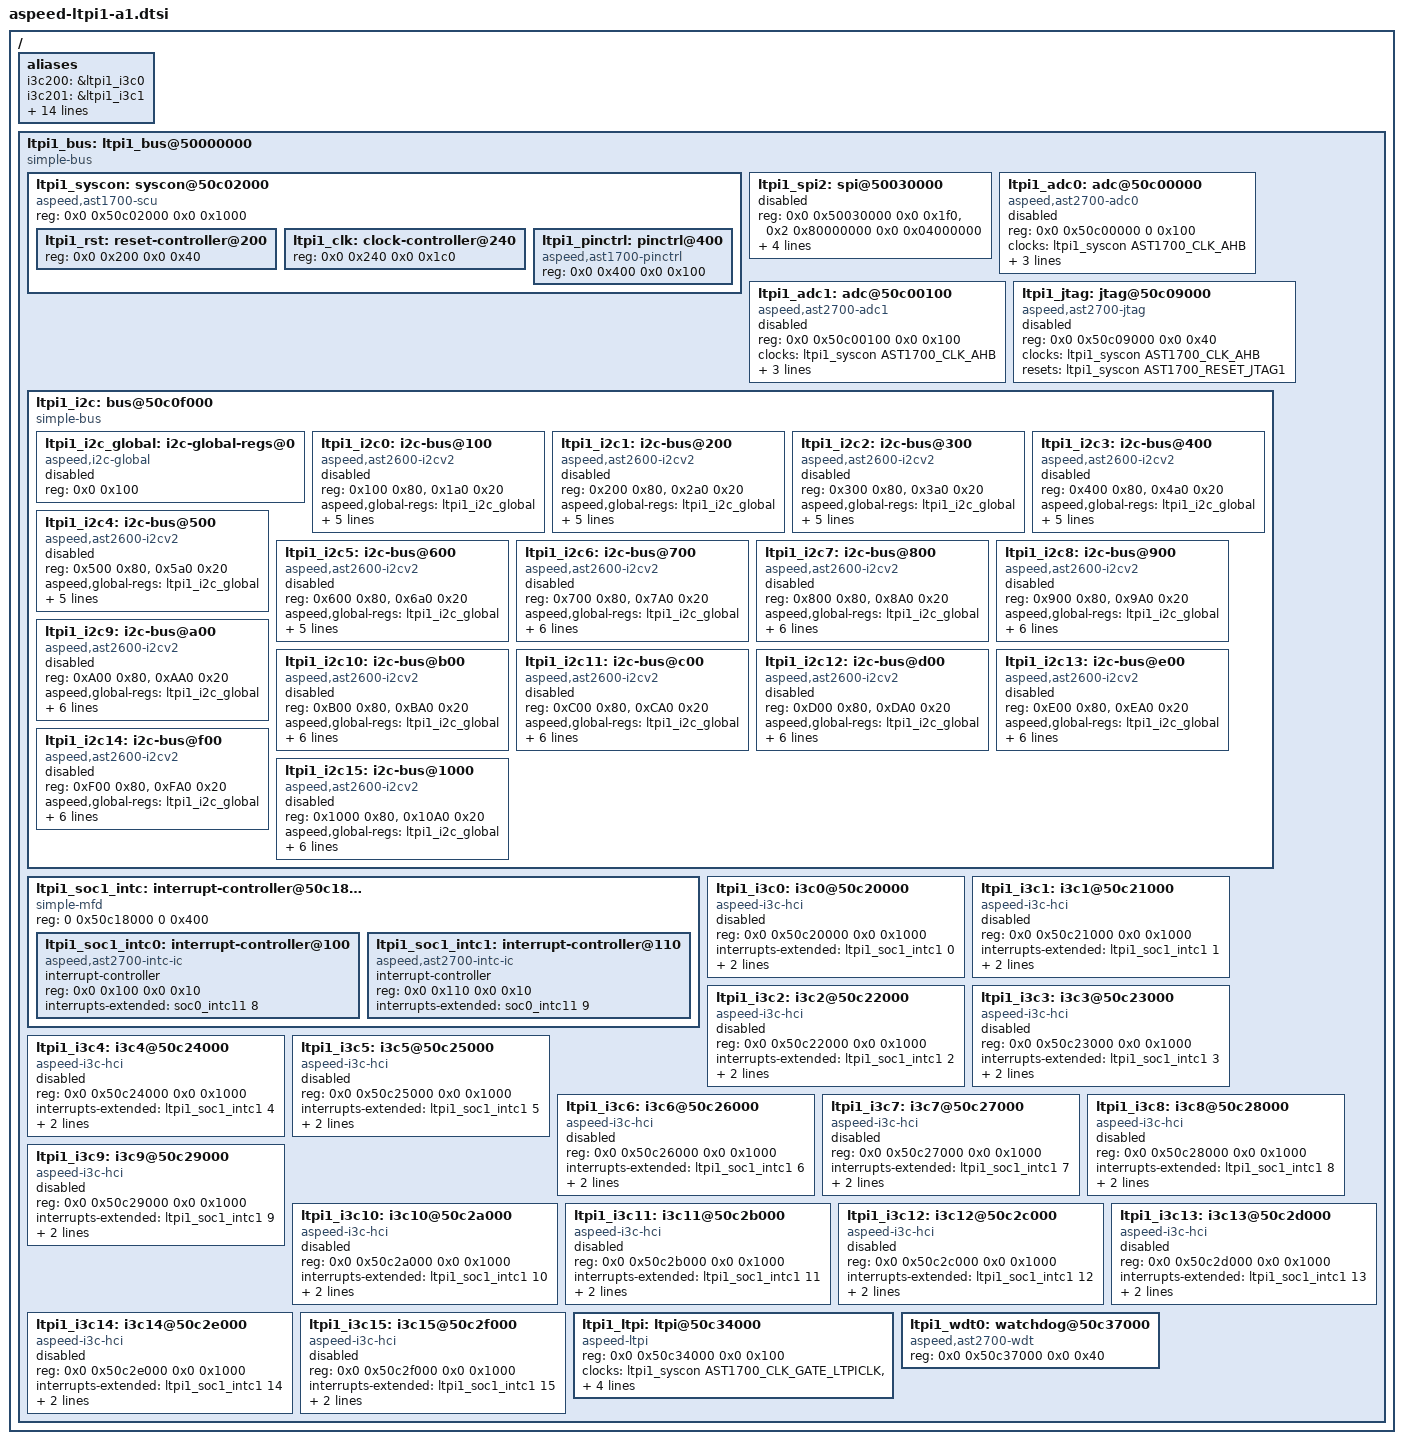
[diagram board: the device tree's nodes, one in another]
// SPDX-License-Identifier: GPL-2.0-or-later
#include <dt-bindings/clock/aspeed,ast1700-clk.h>
#include <dt-bindings/reset/aspeed,ast1700-reset.h>

/ {
	aliases {
		i3c200 = &ltpi1_i3c0;
		i3c201 = &ltpi1_i3c1;
		i3c202 = &ltpi1_i3c2;
		i3c203 = &ltpi1_i3c3;
		i3c204 = &ltpi1_i3c4;
		i3c205 = &ltpi1_i3c5;
		i3c206 = &ltpi1_i3c6;
		i3c207 = &ltpi1_i3c7;
		i3c208 = &ltpi1_i3c8;
		i3c209 = &ltpi1_i3c9;
		i3c210 = &ltpi1_i3c10;
		i3c211 = &ltpi1_i3c11;
		i3c212 = &ltpi1_i3c12;
		i3c213 = &ltpi1_i3c13;
		i3c214 = &ltpi1_i3c14;
		i3c215 = &ltpi1_i3c15;
	};

	ltpi1_bus: ltpi1_bus@50000000 {
		compatible = "simple-bus";
		#address-cells = <2>;
		#size-cells = <2>;
		ranges;

		ltpi1_syscon: syscon@50c02000 {
			compatible = "aspeed,ast1700-scu", "syscon", "simple-mfd";
			reg = <0x0 0x50c02000 0x0 0x1000>;
			ranges = <0x0 0x0 0x0 0x50c02000 0x0 0x1000>;
			#address-cells = <2>;
			#size-cells = <2>;
			#clock-cells = <1>;
			#reset-cells = <1>;

			ltpi1_rst: reset-controller@200 {
				reg = <0x0 0x200 0x0 0x40>;
			};

			ltpi1_clk: clock-controller@240 {
				reg = <0x0 0x240 0x0 0x1c0>;
			};

			ltpi1_pinctrl: pinctrl@400 {
				compatible = "aspeed,ast1700-pinctrl";
				reg = <0x0 0x400 0x0 0x100>;
			};
		};

		ltpi1_spi2: spi@50030000 {
			reg = <0x0 0x50030000 0x0 0x1f0>, <0x2 0x80000000 0x0 0x04000000>;
			#address-cells = <1>;
			#size-cells = <0>;
			clocks = <&ltpi1_syscon AST1700_CLK_AHB>;
			resets = <&ltpi1_syscon AST1700_RESET_SPI2>;
			num-cs = <2>;
			ltpi-base = <0x0 0x54000000>;
			status = "disabled";
		};

		ltpi1_adc0: adc@50c00000 {
			compatible = "aspeed,ast2700-adc0";
			reg = <0x0 0x50c00000 0 0x100>;
			clocks = <&ltpi1_syscon AST1700_CLK_AHB>;
			resets = <&ltpi1_syscon AST1700_RESET_ADC>;
			interrupts-extended = <&ltpi1_soc1_intc0 24>;
			#io-channel-cells = <1>;
			aspeed,scu = <&ltpi1_syscon>;
			status = "disabled";
		};

		ltpi1_adc1: adc@50c00100 {
			compatible = "aspeed,ast2700-adc1";
			reg = <0x0 0x50c00100 0x0 0x100>;
			clocks = <&ltpi1_syscon AST1700_CLK_AHB>;
			resets = <&ltpi1_syscon AST1700_RESET_ADC>;
			interrupts-extended = <&ltpi1_soc1_intc0 24>;
			#io-channel-cells = <1>;
			aspeed,scu = <&ltpi1_syscon>;
			status = "disabled";
		};

		ltpi1_jtag: jtag@50c09000 {
			compatible = "aspeed,ast2700-jtag";
			reg= <0x0 0x50c09000 0x0 0x40>;
			clocks = <&ltpi1_syscon AST1700_CLK_AHB>;
			resets = <&ltpi1_syscon AST1700_RESET_JTAG1>;
			status = "disabled";
		};

		ltpi1_i2c: bus@50c0f000 {
			compatible = "simple-bus";
			#address-cells = <1>;
			#size-cells = <1>;
			ranges = <0x0 0x0 0x50c0f000 0x1100>;
		};

		ltpi1_soc1_intc: interrupt-controller@50c18000 {
			compatible = "simple-mfd";
			reg = <0 0x50c18000 0 0x400>;
			#address-cells = <2>;
			#size-cells = <2>;
			ranges = <0x0 0x0 0x0 0x50c18000 0x0 0x400>;

			ltpi1_soc1_intc0: interrupt-controller@100 {
				#interrupt-cells = <1>;
				interrupt-controller;
				compatible = "aspeed,ast2700-intc-ic";
				reg = <0x0 0x100 0x0 0x10>;
				interrupts-extended = <&soc0_intc11 8>;
			};

			ltpi1_soc1_intc1: interrupt-controller@110 {
				#interrupt-cells = <1>;
				interrupt-controller;
				compatible = "aspeed,ast2700-intc-ic";
				reg = <0x0 0x110 0x0 0x10>;
				interrupts-extended = <&soc0_intc11 9>;
			};
		};

		ltpi1_i3c0: i3c0@50c20000 {
			compatible = "aspeed-i3c-hci";
			#address-cells = <1>;
			#size-cells = <0>;
			reg = <0x0 0x50c20000 0x0 0x1000>;
			interrupts-extended = <&ltpi1_soc1_intc1 0>;
			clocks = <&ltpi1_syscon SCU1_CLK_GATE_I3C0CLK>;
			resets = <&ltpi1_syscon SCU1_RESET_I3C0>;
			status = "disabled";
		};

		ltpi1_i3c1: i3c1@50c21000 {
			compatible = "aspeed-i3c-hci";
			#address-cells = <1>;
			#size-cells = <0>;
			reg = <0x0 0x50c21000 0x0 0x1000>;
			interrupts-extended = <&ltpi1_soc1_intc1 1>;
			clocks = <&ltpi1_syscon SCU1_CLK_GATE_I3C1CLK>;
			resets = <&ltpi1_syscon SCU1_RESET_I3C1>;
			status = "disabled";
		};

		ltpi1_i3c2: i3c2@50c22000 {
			compatible = "aspeed-i3c-hci";
			#address-cells = <1>;
			#size-cells = <0>;
			reg = <0x0 0x50c22000 0x0 0x1000>;
			interrupts-extended = <&ltpi1_soc1_intc1 2>;
			clocks = <&ltpi1_syscon SCU1_CLK_GATE_I3C2CLK>;
			resets = <&ltpi1_syscon SCU1_RESET_I3C2>;
			status = "disabled";
		};

		ltpi1_i3c3: i3c3@50c23000 {
			compatible = "aspeed-i3c-hci";
			#address-cells = <1>;
			#size-cells = <0>;
			reg = <0x0 0x50c23000 0x0 0x1000>;
			interrupts-extended = <&ltpi1_soc1_intc1 3>;
			clocks = <&ltpi1_syscon SCU1_CLK_GATE_I3C3CLK>;
			resets = <&ltpi1_syscon SCU1_RESET_I3C3>;
			status = "disabled";
		};

		ltpi1_i3c4: i3c4@50c24000 {
			compatible = "aspeed-i3c-hci";
			#address-cells = <1>;
			#size-cells = <0>;
			reg = <0x0 0x50c24000 0x0 0x1000>;
			interrupts-extended = <&ltpi1_soc1_intc1 4>;
			clocks = <&ltpi1_syscon AST1700_CLK_GATE_I3C4CLK>;
			resets = <&ltpi1_syscon AST1700_RESET_I3C4>;
			status = "disabled";
		};

		ltpi1_i3c5: i3c5@50c25000 {
			compatible = "aspeed-i3c-hci";
			#address-cells = <1>;
			#size-cells = <0>;
			reg = <0x0 0x50c25000 0x0 0x1000>;
			interrupts-extended = <&ltpi1_soc1_intc1 5>;
			clocks = <&ltpi1_syscon AST1700_CLK_GATE_I3C5CLK>;
			resets = <&ltpi1_syscon AST1700_RESET_I3C5>;
			status = "disabled";
		};

		ltpi1_i3c6: i3c6@50c26000 {
			compatible = "aspeed-i3c-hci";
			#address-cells = <1>;
			#size-cells = <0>;
			reg = <0x0 0x50c26000 0x0 0x1000>;
			interrupts-extended = <&ltpi1_soc1_intc1 6>;
			clocks = <&ltpi1_syscon AST1700_CLK_GATE_I3C6CLK>;
			resets = <&ltpi1_syscon AST1700_RESET_I3C6>;
			status = "disabled";
		};

		ltpi1_i3c7: i3c7@50c27000 {
			compatible = "aspeed-i3c-hci";
			#address-cells = <1>;
			#size-cells = <0>;
			reg = <0x0 0x50c27000 0x0 0x1000>;
			interrupts-extended = <&ltpi1_soc1_intc1 7>;
			clocks = <&ltpi1_syscon AST1700_CLK_GATE_I3C7CLK>;
			resets = <&ltpi1_syscon AST1700_RESET_I3C7>;
			status = "disabled";
		};

		ltpi1_i3c8: i3c8@50c28000 {
			compatible = "aspeed-i3c-hci";
			#address-cells = <1>;
			#size-cells = <0>;
			reg = <0x0 0x50c28000 0x0 0x1000>;
			interrupts-extended = <&ltpi1_soc1_intc1 8>;
			clocks = <&ltpi1_syscon AST1700_CLK_GATE_I3C8CLK>;
			resets = <&ltpi1_syscon AST1700_RESET_I3C8>;
			status = "disabled";
		};

		ltpi1_i3c9: i3c9@50c29000 {
			compatible = "aspeed-i3c-hci";
			#address-cells = <1>;
			#size-cells = <0>;
			reg = <0x0 0x50c29000 0x0 0x1000>;
			interrupts-extended = <&ltpi1_soc1_intc1 9>;
			clocks = <&ltpi1_syscon AST1700_CLK_GATE_I3C9CLK>;
			resets = <&ltpi1_syscon AST1700_RESET_I3C9>;
			status = "disabled";
		};

		ltpi1_i3c10: i3c10@50c2a000 {
			compatible = "aspeed-i3c-hci";
			#address-cells = <1>;
			#size-cells = <0>;
			reg = <0x0 0x50c2a000 0x0 0x1000>;
			interrupts-extended = <&ltpi1_soc1_intc1 10>;
			clocks = <&ltpi1_syscon AST1700_CLK_GATE_I3C10CLK>;
			resets = <&ltpi1_syscon AST1700_RESET_I3C10>;
			status = "disabled";
		};

		ltpi1_i3c11: i3c11@50c2b000 {
			compatible = "aspeed-i3c-hci";
			#address-cells = <1>;
			#size-cells = <0>;
			reg = <0x0 0x50c2b000 0x0 0x1000>;
			interrupts-extended = <&ltpi1_soc1_intc1 11>;
			clocks = <&ltpi1_syscon AST1700_CLK_GATE_I3C11CLK>;
			resets = <&ltpi1_syscon AST1700_RESET_I3C11>;
			status = "disabled";
		};

		ltpi1_i3c12: i3c12@50c2c000 {
			compatible = "aspeed-i3c-hci";
			#address-cells = <1>;
			#size-cells = <0>;
			reg = <0x0 0x50c2c000 0x0 0x1000>;
			interrupts-extended = <&ltpi1_soc1_intc1 12>;
			clocks = <&ltpi1_syscon SCU1_CLK_GATE_I3C12CLK>;
			resets = <&ltpi1_syscon SCU1_RESET_I3C12>;
			status = "disabled";
		};

		ltpi1_i3c13: i3c13@50c2d000 {
			compatible = "aspeed-i3c-hci";
			#address-cells = <1>;
			#size-cells = <0>;
			reg = <0x0 0x50c2d000 0x0 0x1000>;
			interrupts-extended = <&ltpi1_soc1_intc1 13>;
			clocks = <&ltpi1_syscon SCU1_CLK_GATE_I3C13CLK>;
			resets = <&ltpi1_syscon SCU1_RESET_I3C13>;
			status = "disabled";
		};

		ltpi1_i3c14: i3c14@50c2e000 {
			compatible = "aspeed-i3c-hci";
			#address-cells = <1>;
			#size-cells = <0>;
			reg = <0x0 0x50c2e000 0x0 0x1000>;
			interrupts-extended = <&ltpi1_soc1_intc1 14>;
			clocks = <&ltpi1_syscon SCU1_CLK_GATE_I3C14CLK>;
			resets = <&ltpi1_syscon SCU1_RESET_I3C14>;
			status = "disabled";
		};

		ltpi1_i3c15: i3c15@50c2f000 {
			compatible = "aspeed-i3c-hci";
			#address-cells = <1>;
			#size-cells = <0>;
			reg = <0x0 0x50c2f000 0x0 0x1000>;
			interrupts-extended = <&ltpi1_soc1_intc1 15>;
			clocks = <&ltpi1_syscon SCU1_CLK_GATE_I3C15CLK>;
			resets = <&ltpi1_syscon SCU1_RESET_I3C15>;
			status = "disabled";
		};

		ltpi1_ltpi: ltpi@50c34000 {
			compatible = "aspeed-ltpi";
			reg = <0x0 0x50c34000 0x0 0x100>;
			clocks = <&ltpi1_syscon AST1700_CLK_GATE_LTPICLK>,
				 <&ltpi1_syscon AST1700_CLK_GATE_LTPIPHYCLK>;
			clock-names = "ahb", "phy";
			resets = <&ltpi1_syscon AST1700_RESET_LTPI>;
			remote-controller;
			aspeed,scu = <&ltpi1_syscon>;
			status = "okay";
		};

		ltpi1_wdt0: watchdog@50c37000 {
			compatible = "aspeed,ast2700-wdt";
			reg = <0x0 0x50c37000 0x0 0x40>;
		};
	};
};

#include "aspeed-ltpi1-pinctrl-a1.dtsi"

&ltpi1_i2c {
	ltpi1_i2c_global: i2c-global-regs@0 {
		compatible = "aspeed,i2c-global", "simple-mfd", "syscon";
		reg = <0x0 0x100>;
		status = "disabled";
	};

	ltpi1_i2c0: i2c-bus@100 {
		#address-cells = <1>;
		#size-cells = <1>;
		#interrupt-cells = <1>;
		reg = <0x100 0x80>, <0x1a0 0x20>;
		compatible = "aspeed,ast2600-i2cv2";
		aspeed,global-regs = <&ltpi1_i2c_global>;
		clocks = <&ltpi1_syscon AST1700_CLK_APB>;
		resets = <&ltpi1_syscon AST1700_RESET_I2C>;
		interrupts-extended = <&ltpi1_soc1_intc1 0>;
		clock-frequency = <100000>;
		pinctrl-names = "default";
		pinctrl-0 = <&pinctrl_ltpi1_i2c0_default>;
		status = "disabled";
	};

	ltpi1_i2c1: i2c-bus@200 {
		#address-cells = <1>;
		#size-cells = <1>;
		#interrupt-cells = <1>;
		reg = <0x200 0x80>, <0x2a0 0x20>;
		compatible = "aspeed,ast2600-i2cv2";
		aspeed,global-regs = <&ltpi1_i2c_global>;
		clocks = <&ltpi1_syscon AST1700_CLK_APB>;
		resets = <&ltpi1_syscon AST1700_RESET_I2C>;
		interrupts-extended = <&ltpi1_soc1_intc0 1>;
		clock-frequency = <100000>;
		pinctrl-names = "default";
		pinctrl-0 = <&pinctrl_ltpi1_i2c1_default>;
		status = "disabled";
	};

	ltpi1_i2c2: i2c-bus@300 {
		#address-cells = <1>;
		#size-cells = <0>;
		#interrupt-cells = <1>;
		reg = <0x300 0x80>, <0x3a0 0x20>;
		compatible = "aspeed,ast2600-i2cv2";
		aspeed,global-regs = <&ltpi1_i2c_global>;
		clocks = <&ltpi1_syscon AST1700_CLK_APB>;
		resets = <&ltpi1_syscon AST1700_RESET_I2C>;
		interrupts-extended = <&ltpi1_soc1_intc0 2>;
		clock-frequency = <100000>;
		pinctrl-names = "default";
		pinctrl-0 = <&pinctrl_ltpi1_i2c2_default>;
		status = "disabled";
	};

	ltpi1_i2c3: i2c-bus@400 {
		#address-cells = <1>;
		#size-cells = <0>;
		#interrupt-cells = <1>;
		reg = <0x400 0x80>, <0x4a0 0x20>;
		compatible = "aspeed,ast2600-i2cv2";
		aspeed,global-regs = <&ltpi1_i2c_global>;
		clocks = <&ltpi1_syscon AST1700_CLK_APB>;
		resets = <&ltpi1_syscon AST1700_RESET_I2C>;
		interrupts-extended = <&ltpi1_soc1_intc0 3>;
		clock-frequency = <100000>;
		pinctrl-names = "default";
		pinctrl-0 = <&pinctrl_ltpi1_i2c3_default>;
		status = "disabled";
	};

	ltpi1_i2c4: i2c-bus@500 {
		#address-cells = <1>;
		#size-cells = <0>;
		#interrupt-cells = <1>;
		reg = <0x500 0x80>, <0x5a0 0x20>;
		compatible = "aspeed,ast2600-i2cv2";
		aspeed,global-regs = <&ltpi1_i2c_global>;
		clocks = <&ltpi1_syscon AST1700_CLK_APB>;
		resets = <&ltpi1_syscon AST1700_RESET_I2C>;
		clock-frequency = <100000>;
		interrupts-extended = <&ltpi1_soc1_intc0 4>;
		pinctrl-names = "default";
		pinctrl-0 = <&pinctrl_ltpi1_i2c4_default>;
		status = "disabled";
	};

	ltpi1_i2c5: i2c-bus@600 {
		#address-cells = <1>;
		#size-cells = <0>;
		#interrupt-cells = <1>;
		reg = <0x600 0x80>, <0x6a0 0x20>;
		compatible = "aspeed,ast2600-i2cv2";
		aspeed,global-regs = <&ltpi1_i2c_global>;
		clocks = <&ltpi1_syscon AST1700_CLK_APB>;
		resets = <&ltpi1_syscon AST1700_RESET_I2C>;
		interrupts-extended = <&ltpi1_soc1_intc0 5>;
		clock-frequency = <100000>;
		pinctrl-names = "default";
		pinctrl-0 = <&pinctrl_ltpi1_i2c5_default>;
		status = "disabled";
	};

	ltpi1_i2c6: i2c-bus@700 {
		#address-cells = <1>;
		#size-cells = <0>;
		#interrupt-cells = <1>;
		reg = <0x700 0x80>, <0x7A0 0x20>;
		compatible = "aspeed,ast2600-i2cv2";
		aspeed,global-regs = <&ltpi1_i2c_global>;
		aspeed,enable-dma;
		clocks = <&ltpi1_syscon SCU1_CLK_APB>;
		resets = <&ltpi1_syscon SCU1_RESET_I2C>;
		interrupts-extended = <&ltpi1_soc1_intc0 6>;
		clock-frequency = <100000>;
		pinctrl-names = "default";
		pinctrl-0 = <&pinctrl_ltpi1_i2c6_default>;
		status = "disabled";
	};

	ltpi1_i2c7: i2c-bus@800 {
		#address-cells = <1>;
		#size-cells = <0>;
		#interrupt-cells = <1>;
		reg = <0x800 0x80>, <0x8A0 0x20>;
		compatible = "aspeed,ast2600-i2cv2";
		aspeed,global-regs = <&ltpi1_i2c_global>;
		aspeed,enable-dma;
		clocks = <&ltpi1_syscon SCU1_CLK_APB>;
		resets = <&ltpi1_syscon SCU1_RESET_I2C>;
		interrupts-extended = <&ltpi1_soc1_intc0 7>;
		clock-frequency = <100000>;
		pinctrl-names = "default";
		pinctrl-0 = <&pinctrl_ltpi1_i2c7_default>;
		status = "disabled";
	};

	ltpi1_i2c8: i2c-bus@900 {
		#address-cells = <1>;
		#size-cells = <0>;
		#interrupt-cells = <1>;
		reg = <0x900 0x80>, <0x9A0 0x20>;
		compatible = "aspeed,ast2600-i2cv2";
		aspeed,global-regs = <&ltpi1_i2c_global>;
		aspeed,enable-dma;
		clocks = <&ltpi1_syscon SCU1_CLK_APB>;
		resets = <&ltpi1_syscon SCU1_RESET_I2C>;
		interrupts-extended = <&ltpi1_soc1_intc0 8>;
		clock-frequency = <100000>;
		pinctrl-names = "default";
		pinctrl-0 = <&pinctrl_ltpi1_i2c8_default>;
		status = "disabled";
	};

	ltpi1_i2c9: i2c-bus@a00 {
		#address-cells = <1>;
		#size-cells = <0>;
		#interrupt-cells = <1>;
		reg = <0xA00 0x80>, <0xAA0 0x20>;
		compatible = "aspeed,ast2600-i2cv2";
		aspeed,global-regs = <&ltpi1_i2c_global>;
		aspeed,enable-dma;
		clocks = <&ltpi1_syscon SCU1_CLK_APB>;
		resets = <&ltpi1_syscon SCU1_RESET_I2C>;
		interrupts-extended = <&ltpi1_soc1_intc0 9>;
		clock-frequency = <100000>;
		pinctrl-names = "default";
		pinctrl-0 = <&pinctrl_ltpi1_i2c9_default>;
		status = "disabled";
	};

	ltpi1_i2c10: i2c-bus@b00 {
		#address-cells = <1>;
		#size-cells = <0>;
		#interrupt-cells = <1>;
		reg = <0xB00 0x80>, <0xBA0 0x20>;
		compatible = "aspeed,ast2600-i2cv2";
		aspeed,global-regs = <&ltpi1_i2c_global>;
		aspeed,enable-dma;
		clocks = <&ltpi1_syscon SCU1_CLK_APB>;
		resets = <&ltpi1_syscon SCU1_RESET_I2C>;
		interrupts-extended = <&ltpi1_soc1_intc0 10>;
		clock-frequency = <100000>;
		pinctrl-names = "default";
		pinctrl-0 = <&pinctrl_ltpi1_i2c10_default>;
		status = "disabled";
	};

	ltpi1_i2c11: i2c-bus@c00 {
		#address-cells = <1>;
		#size-cells = <0>;
		#interrupt-cells = <1>;
		reg = <0xC00 0x80>, <0xCA0 0x20>;
		compatible = "aspeed,ast2600-i2cv2";
		aspeed,global-regs = <&ltpi1_i2c_global>;
		aspeed,enable-dma;
		clocks = <&ltpi1_syscon SCU1_CLK_APB>;
		resets = <&ltpi1_syscon SCU1_RESET_I2C>;
		interrupts-extended = <&ltpi1_soc1_intc0 11>;
		clock-frequency = <100000>;
		pinctrl-names = "default";
		pinctrl-0 = <&pinctrl_ltpi1_i2c11_default>;
		status = "disabled";
	};

	ltpi1_i2c12: i2c-bus@d00 {
		#address-cells = <1>;
		#size-cells = <0>;
		#interrupt-cells = <1>;
		reg = <0xD00 0x80>, <0xDA0 0x20>;
		compatible = "aspeed,ast2600-i2cv2";
		aspeed,global-regs = <&ltpi1_i2c_global>;
		aspeed,enable-dma;
		clocks = <&ltpi1_syscon SCU1_CLK_APB>;
		resets = <&ltpi1_syscon SCU1_RESET_I2C>;
		interrupts-extended = <&ltpi1_soc1_intc0 12>;
		clock-frequency = <100000>;
		pinctrl-names = "default";
		pinctrl-0 = <&pinctrl_ltpi1_i2c12_default>;
		status = "disabled";
	};

	ltpi1_i2c13: i2c-bus@e00 {
		#address-cells = <1>;
		#size-cells = <0>;
		#interrupt-cells = <1>;
		reg = <0xE00 0x80>, <0xEA0 0x20>;
		compatible = "aspeed,ast2600-i2cv2";
		aspeed,global-regs = <&ltpi1_i2c_global>;
		aspeed,enable-dma;
		clocks = <&ltpi1_syscon SCU1_CLK_APB>;
		resets = <&ltpi1_syscon SCU1_RESET_I2C>;
		interrupts-extended = <&ltpi1_soc1_intc0 13>;
		clock-frequency = <100000>;
		pinctrl-names = "default";
		pinctrl-0 = <&pinctrl_ltpi1_i2c13_default>;
		status = "disabled";
	};

	ltpi1_i2c14: i2c-bus@f00 {
		#address-cells = <1>;
		#size-cells = <0>;
		#interrupt-cells = <1>;
		reg = <0xF00 0x80>, <0xFA0 0x20>;
		compatible = "aspeed,ast2600-i2cv2";
		aspeed,global-regs = <&ltpi1_i2c_global>;
		aspeed,enable-dma;
		clocks = <&ltpi1_syscon SCU1_CLK_APB>;
		resets = <&ltpi1_syscon SCU1_RESET_I2C>;
		interrupts-extended = <&ltpi1_soc1_intc0 14>;
		clock-frequency = <100000>;
		pinctrl-names = "default";
		pinctrl-0 = <&pinctrl_ltpi1_i2c14_default>;
		status = "disabled";
	};

	ltpi1_i2c15: i2c-bus@1000 {
		#address-cells = <1>;
		#size-cells = <0>;
		#interrupt-cells = <1>;
		reg = <0x1000 0x80>, <0x10A0 0x20>;
		compatible = "aspeed,ast2600-i2cv2";
		aspeed,global-regs = <&ltpi1_i2c_global>;
		aspeed,enable-dma;
		clocks = <&ltpi1_syscon SCU1_CLK_APB>;
		resets = <&ltpi1_syscon SCU1_RESET_I2C>;
		interrupts-extended = <&ltpi1_soc1_intc0 15>;
		clock-frequency = <100000>;
		pinctrl-names = "default";
		pinctrl-0 = <&pinctrl_ltpi1_i2c15_default>;
		status = "disabled";
	};
};
